# PY32F040xx register map
Vendor: Puya; Series: PY32F0; File version: 1.0.0
CPU: CM0+ r0p1, little endian, no MPU, no FPU, 4 interrupt priority bits
Registers are 32-bit, read-write, reset 0x0 unless marked. A register's access mark holds for its fields unless they carry their own. Offsets are from the block's base; [hi:lo] are bit positions; {n}, {i} and the like mark numbered series; 'fields as' and 'values as' point back to an identical list.

## TIM1 — Advanced timer
Base 0x40012C00
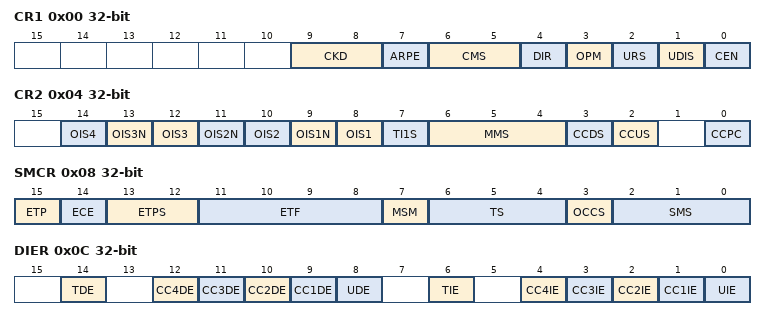
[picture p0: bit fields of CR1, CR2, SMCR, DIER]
0x00 CR1
  [9:8] CKD
    0=NoMult (tDTS = tCK_INT); 1=X2 (tDTS = 2 x tCK_INT); 2=X4 (tDTS = 4 x tCK_INT)
  [7] ARPE
    0=Disabled (TIMx_ARR register is not buffered); 1=Enabled (TIMx_ARR register is buffered)
  [6:5] CMS
    0=EdgeAligned (The counter counts up or down depending on the direction bit); 1=CenterAligned1 (The counter counts up and down alternatively. Output compare interrupt flags are set only when the counter is counting down); 2=CenterAligned2 (The counter counts up and down alternatively. Output compare interrupt flags are set only when the counter is counting up); 3=CenterAligned3 (The counter counts up and down alternatively. Output compare interrupt flags are set both when the counter is counting up or down)
  [4] DIR
    0=Up (Counter used as upcounter); 1=Down (Counter used as downcounter)
  [3] OPM
    0=NotStopped (Counter not stopped at update event); 1=Stopped (Counter stopped at update event)
  [2] URS
    0=AnyEvent (Any of counter overflow/underflow, setting UG, or update through slave mode, generates an update interrupt or DMA request); 1=CounterOnly (Only counter overflow/underflow generates an update interrupt or DMA request)
  [1] UDIS
    0=Enabled (Update event enabled); 1=Disabled (Update event disabled)
  [0] CEN
    0=Disabled (Counter disabled); 1=Enabled (Counter enabled)
0x04 CR2
  [2n+6] OIS{n} (n=1..4)
    0=Off; 1=On (Output Idle state ? (OC? output))
  [13] OIS3N
    0=Off; 1=On (Output Idle state ? (OC?N output))
  [11] OIS2N
    0=Off; 1=On (Output Idle state ? (OC?N output))
  [9] OIS1N
    0=Off; 1=On (Output Idle state ? (OC?N output))
  [7] TI1S
    0=Single (TIMx_CH1 pin is connected to TI1 input); 1=Xor (TIMx_CH1, CH2, CH3 pins are connected to TI1 input (XOR combination))
  [6:4] MMS
    0=Reset (The UG bit from the TIMx_EGR register is used as trigger output); 1=Enable (The counter enable signal, CNT_EN, is used as trigger output); 2=Update (The update event is selected as trigger output); 3=ComparePulse (The trigger output send a positive pulse when the CC1IF flag it to be set, as soon as a capture or a compare match occurred); {v}=CompareOC{v-3} (OC{v-3}REF signal is used as trigger output) (v=4..7)
  [3] CCDS
    0=OnCompare (CCx DMA request sent when CCx event occurs); 1=OnUpdate (CCx DMA request sent when update event occurs)
  [2] CCUS
    0=Bit (When capture/compare control bits are preloaded (CCPC=1), they are updated by setting the COMG bit only); 1=BitOrEdge (When capture/compare control bits are preloaded (CCPC=1), they are updated by setting the COMG bit or when an rising edge occurs on TRGI)
  [0] CCPC
    0=NoPreload (CCxE, CCxNE, OCxM are not updated with event); 1=Preload (CCxE, CCxNE, OCxM are updated with event)
0x08 SMCR (reset mask 0xFFF7)
  [15] ETP
    0=NotInverted (ETR is noninverted, active at high level or rising edge); 1=Inverted (ETR is inverted, active at low level or falling edge)
  [14] ECE
    0=Disabled (External clock mode 2 disabled); 1=Enabled (External clock mode 2 enabled. The counter is clocked by any active edge on the ETRF signal.)
  [13:12] ETPS
    0=Div1 (Prescaler OFF); 1=Div2 (ETRP frequency divided by 2); 2=Div4 (ETRP frequency divided by 4); 3=Div8 (ETRP frequency divided by 8)
  [11:8] ETF
    0=No filter, sampling is done at fDTS; 1=FCK_INT_N2 (fSAMPLING=fCK_INT, N=2); 2=FCK_INT_N4 (fSAMPLING=fCK_INT, N=4); 3=FCK_INT_N8 (fSAMPLING=fCK_INT, N=8); 4=FDTS_Div2_N6 (fSAMPLING=fDTS/2, N=6); 5=FDTS_Div2_N8 (fSAMPLING=fDTS/2, N=8); 6=FDTS_Div4_N6 (fSAMPLING=fDTS/4, N=6); 7=FDTS_Div4_N8 (fSAMPLING=fDTS/4, N=8); 8=FDTS_Div8_N6 (fSAMPLING=fDTS/8, N=6); 9=FDTS_Div8_N8 (fSAMPLING=fDTS/8, N=8); 10=FDTS_Div16_N5 (fSAMPLING=fDTS/16, N=5); 11=FDTS_Div16_N6 (fSAMPLING=fDTS/16, N=6); 12=FDTS_Div16_N8 (fSAMPLING=fDTS/16, N=8); 13=FDTS_Div32_N5 (fSAMPLING=fDTS/32, N=5); 14=FDTS_Div32_N6 (fSAMPLING=fDTS/32, N=6); 15=FDTS_Div32_N8 (fSAMPLING=fDTS/32, N=8)
  [7] MSM
    0=NoSync (No action); 1=Sync (The effect of an event on the trigger input (TRGI) is delayed to allow a perfect synchronization between the current timer and its slaves (through TRGO))
  [6:4] TS
    0=ITR0 (Internal Trigger 0 (ITR0)); 2=ITR2 (Internal Trigger 2 (ITR2)); 4=TI1F_ED (TI1 Edge Detector (TI1F_ED)); 5=TI1FP1 (Filtered Timer Input 1 (TI1FP1)); 6=TI2FP2 (Filtered Timer Input 2 (TI2FP2)); 7=ETRF (External Trigger input (ETRF))
  [3] OCCS
    0=OCREF_CLR_INT connected to the OCREF_CLR input; 1=Etrf (OCREF_CLR_INT connected to ETRF)
  [2:0] SMS
    0=Disabled (Slave mode disabled - if CEN = ‘1 then the prescaler is clocked directly by the internal clock.); 1=Encoder mode 1 - Counter counts up/down on TI2FP1 edge depending on TI1FP2 level; 2=Encoder mode 2 - Counter counts up/down on TI1FP2 edge depending on TI2FP1 level; 3=Encoder mode 3 - Counter counts up/down on both TI1FP1 and TI2FP2 edges depending on the level of the other input; 4=Reset Mode - Rising edge of the selected trigger input (TRGI) reinitializes the counter and generates an update of the registers; 5=Gated Mode - The counter clock is enabled when the trigger input (TRGI) is high. The counter stops (but is not reset) as soon as the trigger becomes low. Both start and stop of the counter are controlled.; 6=Trigger Mode - The counter starts at a rising edge of the trigger TRGI (but it is not reset). Only the start of the counter is controlled.; 7=Ext_Clock_Mode (External Clock Mode 1 - Rising edges of the selected trigger (TRGI) clock the counter.)
0x0C DIER
  [14] TDE
    0=Disabled (Trigger DMA request disabled); 1=Enabled (Trigger DMA request enabled)
  [n+8] CC{n}DE (n=1..4)
    0=Disabled (CCx DMA request disabled); 1=Enabled (CCx DMA request enabled)
  [8] UDE
    0=Disabled (Update DMA request disabled); 1=Enabled (Update DMA request enabled)
  [6] TIE
    0=Disabled (Trigger interrupt disabled); 1=Enabled (Trigger interrupt enabled)
  [n] CC{n}IE (n=1..4)
    0=Disabled (CCx interrupt disabled); 1=Enabled (CCx interrupt enabled)
  [0] UIE
    0=Disabled (Update interrupt disabled); 1=Enabled (Update interrupt enabled)
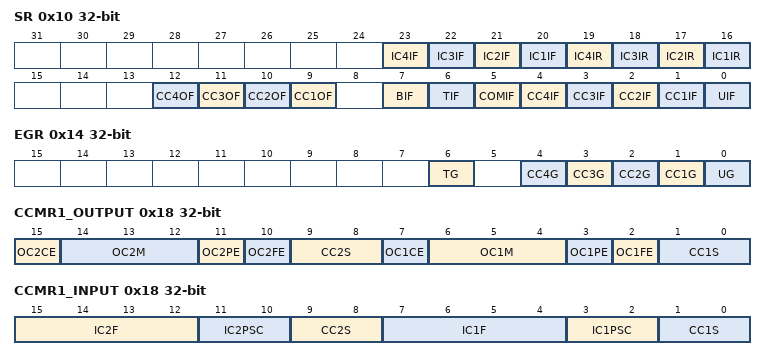
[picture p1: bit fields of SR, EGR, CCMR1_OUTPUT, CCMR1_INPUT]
0x10 SR (reset mask 0x1E5F)
  [23] IC4IF — desc IC3IF
    0=NoCapture (no repeat captures are generated); 1=Capture (falling edge capture event occurs)
  [22] IC3IF
    values as IC4IF
  [21] IC2IF
    values as IC4IF
  [20] IC1IF
    values as IC4IF
  [19] IC4IR — desc IC3IR
    0=NoCapture (no repeat captures are generated); 1=Capture (Rising edge capture event occurs)
  [18] IC3IR
    values as IC4IR
  [17] IC2IR
    values as IC4IR
  [16] IC1IR
    values as IC4IR
  [n+8] CC{n}OF write-0-clears (n=1..4)
    on read: 1=Overcapture (The counter value has been captured in TIMx_CCRx register while CCxOF flag was already set) | on write: 0=Clear flag
  [7] BIF write-0-clears
    on read: 0=no brake event is generated; 1=Brake (Valid level detected on the brake input) | on write: 0=Clear flag
  [6] TIF write-0-clears
    on read: 1=Triggered (Valid edge detected at the TRGI input) | on write: 0=Clear flag
  [5] COMIF write-0-clears
    on read: 0=NoEvt (no COM event is generated); 1=Event (COM interrupt waiting for response) | on write: 0=Clear flag
  [n] CC{n}IF write-0-clears (n=1..4)
    on read: 1=Overcapture (The counter value has been captured in TIMx_CCRx register while CCxIF flag was already set) | on write: 0=Clear flag
  [0] UIF write-0-clears
    on read: 1=Update event waiting for response | on write: 0=Clear flag
0x14 EGR wo
  [6] TG
    1=Trigger interrupt generated
  [4] CC4G
    1=Trigger (If CC1 is an output: CC1IF flag is set, Corresponding interrupt or DMA request is sent if enabled. If CC1 is an input: The current value of the counter is captured in TIMx_CCR1 register)
  [3] CC3G
    values as CC4G
  [2] CC2G
    values as CC4G
  [1] CC1G — Capture/Compare 1 Generation
    values as CC4G
  [0] UG
    1=Trigger (Re-initializes the timer counter and generates an update of the registers)
0x18 CCMR1_OUTPUT
  [15] OC2CE
  [14:12] OC2M
  [11] OC2PE
  [10] OC2FE
  [9:8] CC2S
  [7] OC1CE
  [6:4] OC1M
  [3] OC1PE
    0=Disabled (Preload register on CCR1 disabled. New values written to CCR1 are taken into account immediately); 1=Enabled (Preload register on CCR1 enabled. Preload value is loaded into active register on each update event)
  [2] OC1FE
  [1:0] CC1S
    0=Output (CC1 channel is configured as output)
0x18 CCMR1_INPUT (alternate view of CCMR1_OUTPUT)
  [15:12] IC2F
    values as SMCR.ETF
  [11:10] IC2PSC
    0=NoDiv (no prescaler, capture is done each time an edge is detected on the capture input); 1=Div2 (capture is done once every 2 events); 2=Div4 (capture is done once every 4 events); 3=Div8 (capture is done once every 8 events)
  [9:8] CC2S
    1=TI1 (CC? channel is configured as input, IC1 is mapped on TI1); 2=TI2 (CC? channel is configured as input, IC1 is mapped on TI2); 3=TRC (CC? channel is configured as input, IC1 is mapped on TRC)
  [7:4] IC1F
    values as SMCR.ETF
  [3:2] IC1PSC
    values as IC2PSC
  [1:0] CC1S
    values as CC2S
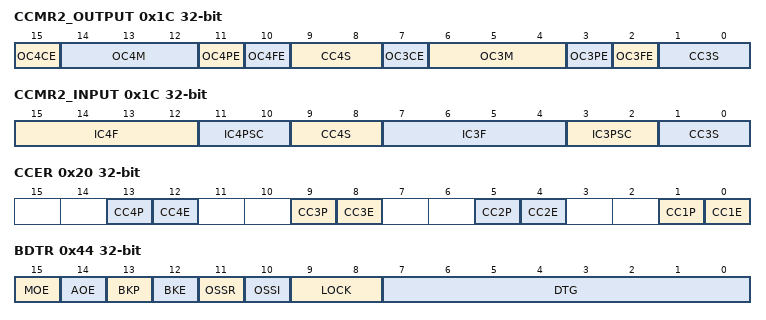
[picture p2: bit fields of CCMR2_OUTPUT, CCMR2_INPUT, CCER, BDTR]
0x1C CCMR2_OUTPUT
  [15] OC4CE
    0=Disabled (Output compare ? clear disabled); 1=Enabled (Output compare ? clear enabled)
  [14:12] OC4M range 0..6
  [11] OC4PE
    0=Disabled (Preload register on CCRx disabled. New values written to CCRx are taken into account immediately); 1=Enabled (Preload register on CCRx enabled. Preload value is loaded into active register on each update event)
  [10] OC4FE
  [9:8] CC4S
    0=Output (CCx channel is configured as output)
  [7] OC3CE
    values as OC4CE
  [6:4] OC3M range 0..6
  [3] OC3PE
    values as OC4PE
  [2] OC3FE
    0=Disabled (Output compare 3 fast disabled); 1=Enabled (Output compare 3 fast enabled)
  [1:0] CC3S
    0=Output (CCx channel is configured as output)
0x1C CCMR2_INPUT (alternate view of CCMR2_OUTPUT)
  [15:12] IC4F
  [11:10] IC4PSC
  [9:8] CC4S
    0=Output (CC4 channel is configured as output); 1=TI4 (CC4 channel is configured as input, IC4 is mapped on TI4); 2=TI3 (CC4 channel is configured as input, IC4 is mapped on TI3); 3=TRC (CC4 channel is configured as input, IC4 is mapped on TRC)
  [7:4] IC3F
  [3:2] IC3PSC
  [1:0] CC3S
    0=Output (CC3 channel is configured as output); 1=TI3 (CC3 channel is configured as input, IC3 is mapped on TI3); 2=TI4 (CC3 channel is configured as input, IC3 is mapped on TI4); 3=TRC (CC3 channel is configured as input, IC3 is mapped on TRC)
0x20 CCER
  [4n-3] CC{n}P (n=1..4)
    0=Disabled (OC? active high); 1=Enabled (OC? active low)
  [4n-4] CC{n}E (n=1..4)
    0=Disabled (Capture Disable); 1=Enabled (Capture Enable)
0x24 CNT
  [15:0] CNT
0x28 PSC
  [15:0] PSC
0x2C ARR reset 0xFFFF
  [15:0] ARR
0x30 RCR reset 0xFFFF
  [7:0] REP
{0x30+4i} CCR{i} (i=1..4)
  [15:0] CCR{i}
0x44 BDTR
  [15] MOE
    0=Disabled (OC and OCN outputs are disabled or forced to idle state); 1=Enabled (OC and OCN outputs are enabled if their respective enable bits are set (CCxE, CCxNE in TIMx_CCER register))
  [14] AOE
    0=Disabled (MOE can be set only by software); 1=Enabled (MOE can be set by software or automatically at the next update event (if the break input is not be active) Note: This bit cannot be modified as long as LOCK level 1 has been programmed (LOCK bits in TIMx_BDTR register))
  [13] BKP
    0=Low (Brake input active low); 1=High (Brake intput active high)
  [12] BKE
    0=Disabled (brake input (BRK and BRK_ACTH) is disabled); 1=Enabled (Brake input (BRK and BRK_ACTH) is enabled)
  [11] OSSR
    0=Disabled (When inactive, OC/OCN outputs are disabled (OC/OCN enable output signal = 0)); 1=Enabled (When inactive, OC/OCN outputs are enabled with their inactive level as soon as CCxE = 1 or CCxNE = 1. Then, OC/OCN enable output signal = 1)
  [10] OSSI
    0=Disabled (When inactive, OC/OCN outputs are disabled (OC/OCN enable output signal = 0)); 1=Enabled (When inactive, OC/OCN outputs are forced first with their idle level as soon as CCxE = 1 or CCxNE = 1. OC/OCN enable output signal = 1))
  [9:8] LOCK
    0=Off (LOCK OFF - No bit is write protected); 1=Lvl1 (LOCK Level 1 = DTG bits in TIMx_BDTR register, OISx and OISxN bits in TIMx_CR2 register and BKE/BKP/AOE bits in TIMx_BDTR register can no longer be written); 2=Lvl2 (LOCK Level 2 = LOCK Level 1 + CC Polarity bits (CCxP/CCxNP bits in TIMx_CCER register, as long as the related channel is configured in output through the CCxS bits) as well as OSSR and OSSI bits can no longer be written); 3=Lvl3 (LOCK Level 3 = LOCK Level 2 + CC Control bits (OCxM and OCxPE bits in TIMx_CCMRx registers, as long as the related channel is configured in output through the CCxS bits) can no longer be written)
  [7:0] DTG
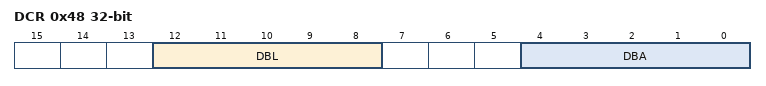
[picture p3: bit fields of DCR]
0x48 DCR
  [12:8] DBL range 0..18, [4:0] DBA
0x4C DMAR
  [15:0] DMAB

## TIM2 — desc TIM
Base 0x40000000
Same registers: TIM3 0x40000400
Registers as TIM1, without RCR, BDTR; these are added or differ:
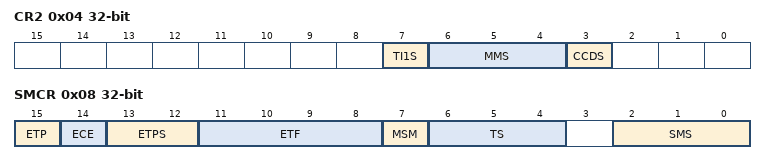
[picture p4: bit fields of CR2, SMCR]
0x04 CR2
  [7] TI1S
    0=Single (TIMx_CH1 pin is connected to TI1 input); 1=Xor (TIMx_CH1, CH2, CH3 pins are connected to TI1 input (XOR combination))
  [6:4] MMS
    values as TIM1.CR2.MMS
  [3] CCDS
    0=OnCompare (CCx DMA request sent when CCx event occurs); 1=OnUpdate (CCx DMA request sent when update event occurs)
0x08 SMCR
  [15] ETP
    0=NotInverted (ETR is noninverted, active at high level or rising edge); 1=Inverted (ETR is inverted, active at low level or falling edge)
  [14] ECE
    0=Disabled (External clock mode 2 disabled); 1=Enabled (External clock mode 2 enabled. The counter is clocked by any active edge on the ETRF signal.)
  [13:12] ETPS
    0=Div1 (Prescaler OFF); 1=Div2 (ETRP frequency divided by 2); 2=Div4 (ETRP frequency divided by 4); 3=Div8 (ETRP frequency divided by 8)
  [11:8] ETF
    values as TIM1.SMCR.ETF
  [7] MSM
    0=NoSync (No action); 1=Sync (The effect of an event on the trigger input (TRGI) is delayed to allow a perfect synchronization between the current timer and its slaves (through TRGO))
  [6:4] TS
    values as TIM1.SMCR.TS
  [2:0] SMS
    values as TIM1.SMCR.SMS

## TIM6 — desc TIM
Base 0x40001000
Same registers: TIM7 0x40001400
Registers as TIM2, without SMCR, CCMR1_OUTPUT, CCMR1_INPUT, CCMR2_OUTPUT, CCMR2_INPUT, CCER, CCR{n} (n=1..4), DCR, DMAR; these are added or differ:
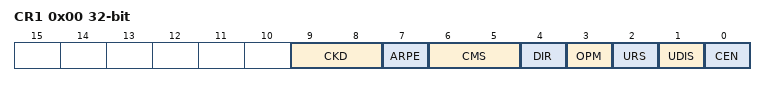
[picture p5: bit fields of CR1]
0x00 CR1
  [9:8] CKD
    0=NoMult (tDTS = tCK_INT); 1=X2 (tDTS = 2 x tCK_INT); 2=X4 (tDTS = 4 x tCK_INT)
  [7] ARPE
    0=Disabled (TIMx_ARR register is not buffered); 1=Enabled (TIMx_ARR register is buffered)
  [6:5] CMS
    values as TIM1.CR1.CMS
  [4] DIR
  [3] OPM
    0=NotStopped (Counter not stopped at update event); 1=Stopped (Counter stopped at update event)
  [2] URS
    values as TIM1.CR1.URS
  [1] UDIS
    0=Enabled (Update event enabled); 1=Disabled (Update event disabled)
  [0] CEN
    0=Disabled (Counter disabled); 1=Enabled (Counter enabled)

## TIM14 — General purpose timer
Base 0x40002000
Registers as TIM6, without CR2; these are added or differ:
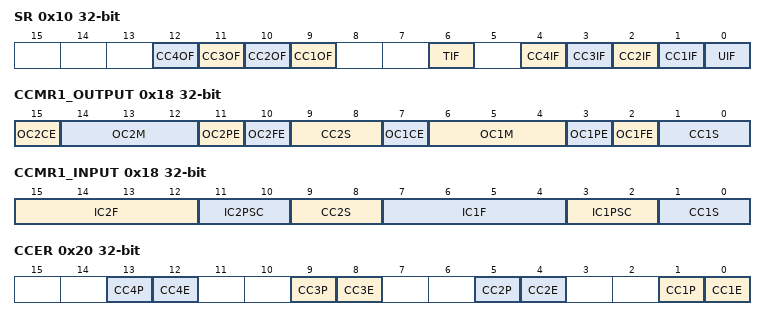
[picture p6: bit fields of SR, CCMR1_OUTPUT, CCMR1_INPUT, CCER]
0x10 SR
  [n+8] CC{n}OF write-0-clears (n=1..4)
    on read: 1=Overcapture (The counter value has been captured in TIMx_CCRx register while CCxOF flag was already set) | on write: 0=Clear flag
  [6] TIF write-0-clears
    on read: 1=Triggered (Valid edge detected at the TRGI input) | on write: 0=Clear flag
  [n] CC{n}IF write-0-clears (n=1..4)
    on read: 1=Overcapture (The counter value has been captured in TIMx_CCRx register while CCxIF flag was already set) | on write: 0=Clear flag
  [0] UIF write-0-clears
    on read: 1=Update event waiting for response | on write: 0=Clear flag
0x18 CCMR1_OUTPUT
  [15] OC2CE, [14:12] OC2M, [11] OC2PE, [10] OC2FE, [9:8] CC2S, [7] OC1CE, [6:4] OC1M, [3] OC1PE, [2] OC1FE, [1:0] CC1S
0x18 CCMR1_INPUT (alternate view of CCMR1_OUTPUT)
  [15:12] IC2F, [11:10] IC2PSC, [9:8] CC2S, [7:4] IC1F, [3:2] IC1PSC, [1:0] CC1S
0x20 CCER
  [4n-3] CC{n}P (n=1..4), [4n-4] CC{n}E (n=1..4)
0x34 CCR1
  [15:0] CCR1
0x50 OR
  [1:0] TI1_RMP

## TIM15
Base 0x40014000
Registers as TIM14, without OR; these are added or differ:
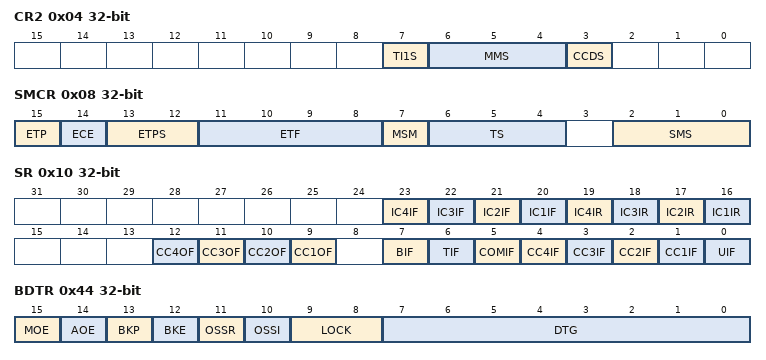
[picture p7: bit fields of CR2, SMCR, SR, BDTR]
0x04 CR2
  [7] TI1S, [6:4] MMS, [3] CCDS
0x08 SMCR
  [15] ETP, [14] ECE, [13:12] ETPS, [11:8] ETF, [7] MSM, [6:4] TS, [2:0] SMS
0x10 SR (reset mask 0x1E5F)
  [23] IC4IF — desc IC3IF
  [22] IC3IF
  [21] IC2IF
  [20] IC1IF
  [19] IC4IR — desc IC3IR
  [18] IC3IR
  [17] IC2IR
  [16] IC1IR
  [n+8] CC{n}OF write-0-clears (n=1..4)
    on read: 1=Overcapture (The counter value has been captured in TIMx_CCRx register while CCxOF flag was already set) | on write: 0=Clear flag
  [7] BIF
  [6] TIF write-0-clears
    on read: 1=Triggered (Valid edge detected at the TRGI input) | on write: 0=Clear flag
  [5] COMIF
  [n] CC{n}IF write-0-clears (n=1..4)
    on read: 1=Overcapture (The counter value has been captured in TIMx_CCRx register while CCxIF flag was already set) | on write: 0=Clear flag
  [0] UIF write-0-clears
    on read: 1=Update event waiting for response | on write: 0=Clear flag
0x30 RCR reset 0xFFFF
  [7:0] REP
0x38 CCR2
  [15:0] CCR2
0x44 BDTR
  [15] MOE, [14] AOE, [13] BKP, [12] BKE, [11] OSSR, [10] OSSI, [9:8] LOCK, [7:0] DTG
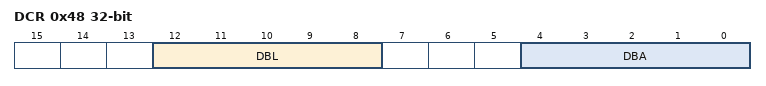
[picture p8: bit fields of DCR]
0x48 DCR
  [12:8] DBL, [4:0] DBA
0x4C DMAR
  [15:0] DMAB

## TIM16 — General purpose timer
Base 0x40014400
Same registers: TIM17 0x40014800
Registers as TIM15, without SMCR, CCR2.
